AUTOSAR XML (schema 4-2-2)
package /STELLANTIS/EPT/ASWCs
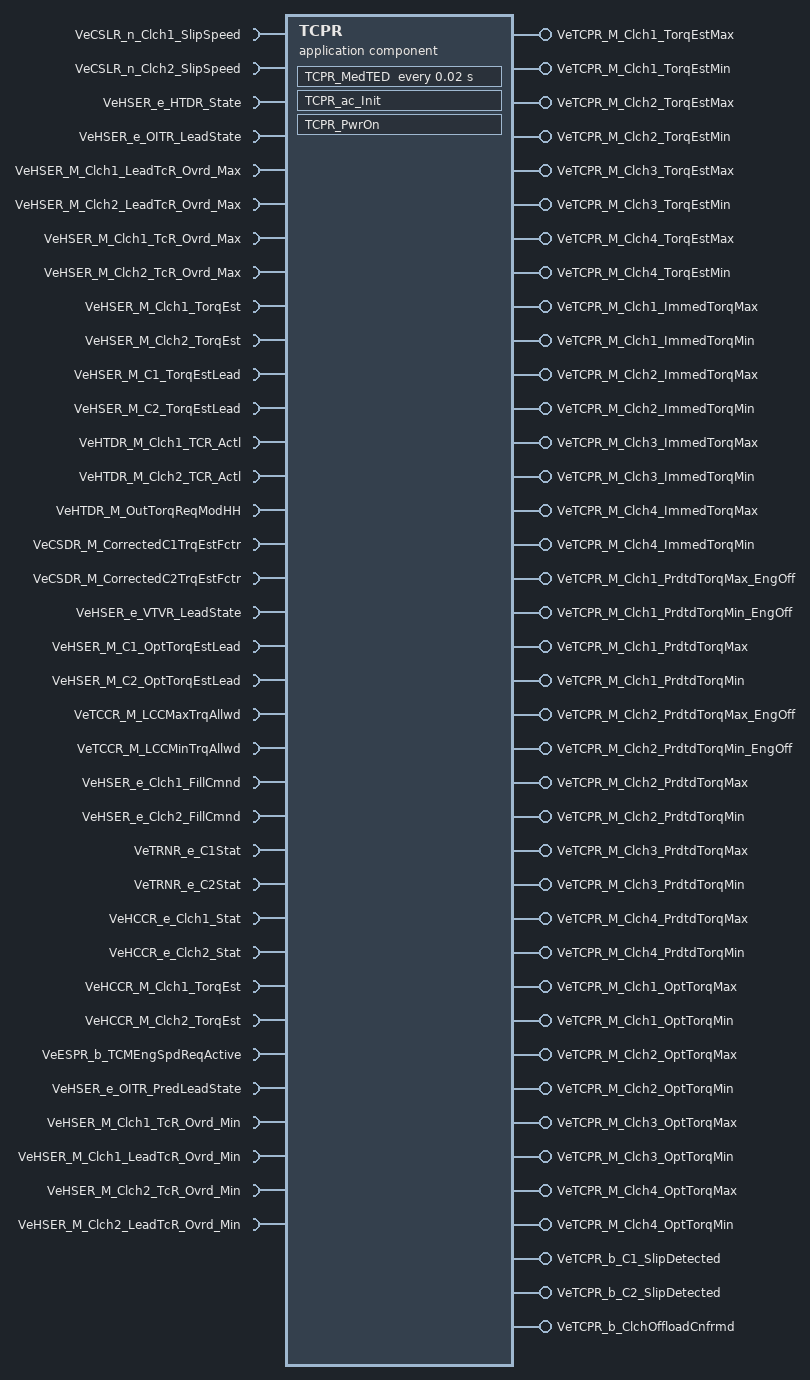
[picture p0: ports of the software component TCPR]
  application sw component type TCPR
    36 x require port:
      VeCSLR_n_Clch1_SlipSpeed: variation-point={short-label=vpVeCSLR_n_Clch1_SlipSpeed, sw-syscond=1}, nonqueued-receiver-com-spec{data-element=Value, init-value=0}, required-interface=VeCSLR_n_Clch1_SlipSpeed
      VeCSLR_n_Clch2_SlipSpeed: variation-point={short-label=vpVeCSLR_n_Clch2_SlipSpeed, sw-syscond=1}, nonqueued-receiver-com-spec{data-element=Value, init-value=0}, required-interface=VeCSLR_n_Clch2_SlipSpeed
      VeHSER_e_HTDR_State: variation-point={short-label=vpVeHSER_e_HTDR_State, sw-syscond=1}, nonqueued-receiver-com-spec{data-element=Value, init-value=CeHSER_e_Neut_State}, required-interface=VeHSER_e_HTDR_State
      VeHSER_e_OITR_LeadState: variation-point={short-label=vpVeHSER_e_OITR_LeadState, sw-syscond=1}, nonqueued-receiver-com-spec{data-element=Value, init-value=CeHSER_e_Neut_State}, required-interface=VeHSER_e_OITR_LeadState
      VeHSER_M_Clch1_LeadTcR_Ovrd_Max: variation-point={short-label=vpVeHSER_M_Clch1_LeadTcR_Ovrd_Max, sw-syscond=1}, nonqueued-receiver-com-spec{data-element=Value, init-value=0}, required-interface=VeHSER_M_Clch1_LeadTcR_Ovrd_Max
      VeHSER_M_Clch2_LeadTcR_Ovrd_Max: variation-point={short-label=vpVeHSER_M_Clch2_LeadTcR_Ovrd_Max, sw-syscond=1}, nonqueued-receiver-com-spec{data-element=Value, init-value=0}, required-interface=VeHSER_M_Clch2_LeadTcR_Ovrd_Max
      VeHSER_M_Clch1_TcR_Ovrd_Max: variation-point={short-label=vpVeHSER_M_Clch1_TcR_Ovrd_Max, sw-syscond=1}, nonqueued-receiver-com-spec{data-element=Value, init-value=0}, required-interface=VeHSER_M_Clch1_TcR_Ovrd_Max
      VeHSER_M_Clch2_TcR_Ovrd_Max: variation-point={short-label=vpVeHSER_M_Clch2_TcR_Ovrd_Max, sw-syscond=1}, nonqueued-receiver-com-spec{data-element=Value, init-value=0}, required-interface=VeHSER_M_Clch2_TcR_Ovrd_Max
      VeHSER_M_Clch1_TorqEst: variation-point={short-label=vpVeHSER_M_Clch1_TorqEst, sw-syscond=1}, nonqueued-receiver-com-spec{data-element=Value, init-value=0}, required-interface=VeHSER_M_Clch1_TorqEst
      VeHSER_M_Clch2_TorqEst: variation-point={short-label=vpVeHSER_M_Clch2_TorqEst, sw-syscond=1}, nonqueued-receiver-com-spec{data-element=Value, init-value=0}, required-interface=VeHSER_M_Clch2_TorqEst
      VeHSER_M_C1_TorqEstLead: variation-point={short-label=vpVeHSER_M_C1_TorqEstLead, sw-syscond=1}, nonqueued-receiver-com-spec{data-element=Value, init-value=0}, required-interface=VeHSER_M_C1_TorqEstLead
      VeHSER_M_C2_TorqEstLead: variation-point={short-label=vpVeHSER_M_C2_TorqEstLead, sw-syscond=1}, nonqueued-receiver-com-spec{data-element=Value, init-value=0}, required-interface=VeHSER_M_C2_TorqEstLead
      VeHTDR_M_Clch1_TCR_Actl: variation-point={short-label=vpVeHTDR_M_Clch1_TCR_Actl, sw-syscond=1}, nonqueued-receiver-com-spec{data-element=Value, init-value=0}, required-interface=VeHTDR_M_Clch1_TCR_Actl
      VeHTDR_M_Clch2_TCR_Actl: variation-point={short-label=vpVeHTDR_M_Clch2_TCR_Actl, sw-syscond=1}, nonqueued-receiver-com-spec{data-element=Value, init-value=0}, required-interface=VeHTDR_M_Clch2_TCR_Actl
      VeHTDR_M_OutTorqReqModHH: variation-point={short-label=vpVeHTDR_M_OutTorqReqModHH, sw-syscond=1}, nonqueued-receiver-com-spec{data-element=Value, init-value=0}, required-interface=VeHTDR_M_OutTorqReqModHH
      VeCSDR_M_CorrectedC1TrqEstFctr: variation-point={short-label=vpVeCSDR_M_CorrectedC1TrqEstFctr, sw-syscond=1}, nonqueued-receiver-com-spec{data-element=Value, init-value=0}, required-interface=VeCSDR_M_CorrectedC1TrqEstFctr
      VeCSDR_M_CorrectedC2TrqEstFctr: variation-point={short-label=vpVeCSDR_M_CorrectedC2TrqEstFctr, sw-syscond=1}, nonqueued-receiver-com-spec{data-element=Value, init-value=0}, required-interface=VeCSDR_M_CorrectedC2TrqEstFctr
      VeHSER_e_VTVR_LeadState: variation-point={short-label=vpVeHSER_e_VTVR_LeadState, sw-syscond=1}, nonqueued-receiver-com-spec{data-element=Value, init-value=CeHSER_e_Neut_State}, required-interface=VeHSER_e_VTVR_LeadState
      VeHSER_M_C1_OptTorqEstLead: variation-point={short-label=vpVeHSER_M_C1_OptTorqEstLead, sw-syscond=1}, nonqueued-receiver-com-spec{data-element=Value, init-value=0}, required-interface=VeHSER_M_C1_OptTorqEstLead
      VeHSER_M_C2_OptTorqEstLead: variation-point={short-label=vpVeHSER_M_C2_OptTorqEstLead, sw-syscond=1}, nonqueued-receiver-com-spec{data-element=Value, init-value=0}, required-interface=VeHSER_M_C2_OptTorqEstLead
      VeTCCR_M_LCCMaxTrqAllwd: variation-point={short-label=vpVeTCCR_M_LCCMaxTrqAllwd, sw-syscond=1}, nonqueued-receiver-com-spec{data-element=Value, init-value=0}, required-interface=VeTCCR_M_LCCMaxTrqAllwd
      VeTCCR_M_LCCMinTrqAllwd: variation-point={short-label=vpVeTCCR_M_LCCMinTrqAllwd, sw-syscond=1}, nonqueued-receiver-com-spec{data-element=Value, init-value=0}, required-interface=VeTCCR_M_LCCMinTrqAllwd
      VeHSER_e_Clch1_FillCmnd: variation-point={short-label=vpVeHSER_e_Clch1_FillCmnd, sw-syscond=1}, nonqueued-receiver-com-spec{data-element=Value, init-value=CeHSER_e_ClchExhstCmpltly}, required-interface=VeHSER_e_Clch1_FillCmnd
      VeHSER_e_Clch2_FillCmnd: variation-point={short-label=vpVeHSER_e_Clch2_FillCmnd, sw-syscond=1}, nonqueued-receiver-com-spec{data-element=Value, init-value=CeHSER_e_ClchExhstCmpltly}, required-interface=VeHSER_e_Clch2_FillCmnd
      VeTRNR_e_C1Stat: variation-point={short-label=vpVeTRNR_e_C1Stat, sw-syscond=1}, nonqueued-receiver-com-spec{data-element=Value, init-value=CeHCCR_e_ClInvalid}, required-interface=VeTRNR_e_C1Stat
      VeTRNR_e_C2Stat: variation-point={short-label=vpVeTRNR_e_C2Stat, sw-syscond=1}, nonqueued-receiver-com-spec{data-element=Value, init-value=CeHCCR_e_ClInvalid}, required-interface=VeTRNR_e_C2Stat
      VeHCCR_e_Clch1_Stat: nonqueued-receiver-com-spec{data-element=Value, init-value=CeHCCR_e_ClInvalid}, required-interface=VeHCCR_e_Clch1_Stat
      VeHCCR_e_Clch2_Stat: nonqueued-receiver-com-spec{data-element=Value, init-value=CeHCCR_e_ClInvalid}, required-interface=VeHCCR_e_Clch2_Stat
      VeHCCR_M_Clch1_TorqEst: variation-point={short-label=vpVeHCCR_M_Clch1_TorqEst, sw-syscond=1}, nonqueued-receiver-com-spec{data-element=Value, init-value=0}, required-interface=VeHCCR_M_Clch1_TorqEst
      VeHCCR_M_Clch2_TorqEst: variation-point={short-label=vpVeHCCR_M_Clch2_TorqEst, sw-syscond=1}, nonqueued-receiver-com-spec{data-element=Value, init-value=0}, required-interface=VeHCCR_M_Clch2_TorqEst
      VeESPR_b_TCMEngSpdReqActive: variation-point={short-label=vpVeESPR_b_TCMEngSpdReqActive, sw-syscond=1}, nonqueued-receiver-com-spec{data-element=Value, init-value=0}, required-interface=VeESPR_b_TCMEngSpdReqActive
      VeHSER_e_OITR_PredLeadState: variation-point={short-label=vpVeHSER_e_OITR_PredLeadState, sw-syscond=1}, nonqueued-receiver-com-spec{data-element=Value, init-value=CeHSER_e_Neut_State}, required-interface=VeHSER_e_OITR_PredLeadState
      VeHSER_M_Clch1_TcR_Ovrd_Min: variation-point={short-label=vpVeHSER_M_Clch1_TcR_Ovrd_Min, sw-syscond=1}, nonqueued-receiver-com-spec{data-element=Value, init-value=0}, required-interface=VeHSER_M_Clch1_TcR_Ovrd_Min
      VeHSER_M_Clch1_LeadTcR_Ovrd_Min: variation-point={short-label=vpVeHSER_M_Clch1_LeadTcR_Ovrd_Min, sw-syscond=1}, nonqueued-receiver-com-spec{data-element=Value, init-value=0}, required-interface=VeHSER_M_Clch1_LeadTcR_Ovrd_Min
      VeHSER_M_Clch2_TcR_Ovrd_Min: variation-point={short-label=vpVeHSER_M_Clch2_TcR_Ovrd_Min, sw-syscond=1}, nonqueued-receiver-com-spec{data-element=Value, init-value=0}, required-interface=VeHSER_M_Clch2_TcR_Ovrd_Min
      VeHSER_M_Clch2_LeadTcR_Ovrd_Min: variation-point={short-label=vpVeHSER_M_Clch2_LeadTcR_Ovrd_Min, sw-syscond=1}, nonqueued-receiver-com-spec{data-element=Value, init-value=0}, required-interface=VeHSER_M_Clch2_LeadTcR_Ovrd_Min
    39 x provide port, all with nonqueued-sender-com-spec{data-element=Value, init-value=0}:
      VeTCPR_M_Clch1_TorqEstMax: provided-interface=VeTCPR_M_Clch1_TorqEstMax
      VeTCPR_M_Clch1_TorqEstMin: provided-interface=VeTCPR_M_Clch1_TorqEstMin
      VeTCPR_M_Clch2_TorqEstMax: provided-interface=VeTCPR_M_Clch2_TorqEstMax
      VeTCPR_M_Clch2_TorqEstMin: provided-interface=VeTCPR_M_Clch2_TorqEstMin
      VeTCPR_M_Clch3_TorqEstMax: provided-interface=VeTCPR_M_Clch3_TorqEstMax
      VeTCPR_M_Clch3_TorqEstMin: provided-interface=VeTCPR_M_Clch3_TorqEstMin
      VeTCPR_M_Clch4_TorqEstMax: provided-interface=VeTCPR_M_Clch4_TorqEstMax
      VeTCPR_M_Clch4_TorqEstMin: provided-interface=VeTCPR_M_Clch4_TorqEstMin
      VeTCPR_M_Clch1_ImmedTorqMax: provided-interface=VeTCPR_M_Clch1_ImmedTorqMax
      VeTCPR_M_Clch1_ImmedTorqMin: provided-interface=VeTCPR_M_Clch1_ImmedTorqMin
      VeTCPR_M_Clch2_ImmedTorqMax: provided-interface=VeTCPR_M_Clch2_ImmedTorqMax
      VeTCPR_M_Clch2_ImmedTorqMin: provided-interface=VeTCPR_M_Clch2_ImmedTorqMin
      VeTCPR_M_Clch3_ImmedTorqMax: provided-interface=VeTCPR_M_Clch3_ImmedTorqMax
      VeTCPR_M_Clch3_ImmedTorqMin: provided-interface=VeTCPR_M_Clch3_ImmedTorqMin
      VeTCPR_M_Clch4_ImmedTorqMax: provided-interface=VeTCPR_M_Clch4_ImmedTorqMax
      VeTCPR_M_Clch4_ImmedTorqMin: provided-interface=VeTCPR_M_Clch4_ImmedTorqMin
      VeTCPR_M_Clch1_PrdtdTorqMax_EngOff: provided-interface=VeTCPR_M_Clch1_PrdtdTorqMax_EngOff
      VeTCPR_M_Clch1_PrdtdTorqMin_EngOff: provided-interface=VeTCPR_M_Clch1_PrdtdTorqMin_EngOff
      VeTCPR_M_Clch1_PrdtdTorqMax: provided-interface=VeTCPR_M_Clch1_PrdtdTorqMax
      VeTCPR_M_Clch1_PrdtdTorqMin: provided-interface=VeTCPR_M_Clch1_PrdtdTorqMin
      VeTCPR_M_Clch2_PrdtdTorqMax_EngOff: provided-interface=VeTCPR_M_Clch2_PrdtdTorqMax_EngOff
      VeTCPR_M_Clch2_PrdtdTorqMin_EngOff: provided-interface=VeTCPR_M_Clch2_PrdtdTorqMin_EngOff
      VeTCPR_M_Clch2_PrdtdTorqMax: provided-interface=VeTCPR_M_Clch2_PrdtdTorqMax
      VeTCPR_M_Clch2_PrdtdTorqMin: provided-interface=VeTCPR_M_Clch2_PrdtdTorqMin
      VeTCPR_M_Clch3_PrdtdTorqMax: provided-interface=VeTCPR_M_Clch3_PrdtdTorqMax
      VeTCPR_M_Clch3_PrdtdTorqMin: provided-interface=VeTCPR_M_Clch3_PrdtdTorqMin
      VeTCPR_M_Clch4_PrdtdTorqMax: provided-interface=VeTCPR_M_Clch4_PrdtdTorqMax
      VeTCPR_M_Clch4_PrdtdTorqMin: provided-interface=VeTCPR_M_Clch4_PrdtdTorqMin
      VeTCPR_M_Clch1_OptTorqMax: provided-interface=VeTCPR_M_Clch1_OptTorqMax
      VeTCPR_M_Clch1_OptTorqMin: provided-interface=VeTCPR_M_Clch1_OptTorqMin
      VeTCPR_M_Clch2_OptTorqMax: provided-interface=VeTCPR_M_Clch2_OptTorqMax
      VeTCPR_M_Clch2_OptTorqMin: provided-interface=VeTCPR_M_Clch2_OptTorqMin
      VeTCPR_M_Clch3_OptTorqMax: provided-interface=VeTCPR_M_Clch3_OptTorqMax
      VeTCPR_M_Clch3_OptTorqMin: provided-interface=VeTCPR_M_Clch3_OptTorqMin
      VeTCPR_M_Clch4_OptTorqMax: provided-interface=VeTCPR_M_Clch4_OptTorqMax
      VeTCPR_M_Clch4_OptTorqMin: provided-interface=VeTCPR_M_Clch4_OptTorqMin
      VeTCPR_b_C1_SlipDetected: provided-interface=VeTCPR_b_C1_SlipDetected
      VeTCPR_b_C2_SlipDetected: provided-interface=VeTCPR_b_C2_SlipDetected
      VeTCPR_b_ClchOffloadCnfrmd: provided-interface=VeTCPR_b_ClchOffloadCnfrmd
    behavior IB_TCPR: data-type-mapping=msADTtoIDTMapping, handle-termination-and-restart=NO-SUPPORT
      timing event Event_MedTED: start-on-event=TCPR_MedTED, period=0.02
      init event Event_TCPR_ac_Init: start-on-event=TCPR_ac_Init
      init event Event_PwrOn: start-on-event=TCPR_PwrOn
      runnable TCPR_ac_Init
      runnable TCPR_PwrOn
        data-send-points:
          39 x access:
            OUT_VeTCPR_M_Clch1_TorqEstMax_Value: accessed-variable=VeTCPR_M_Clch1_TorqEstMax.Value
            OUT_VeTCPR_M_Clch1_TorqEstMin_Value: accessed-variable=VeTCPR_M_Clch1_TorqEstMin.Value
            OUT_VeTCPR_M_Clch2_ImmedTorqMax_Value: accessed-variable=VeTCPR_M_Clch2_ImmedTorqMax.Value
            OUT_VeTCPR_M_Clch2_ImmedTorqMin_Value: accessed-variable=VeTCPR_M_Clch2_ImmedTorqMin.Value
            OUT_VeTCPR_M_Clch3_ImmedTorqMax_Value: accessed-variable=VeTCPR_M_Clch3_ImmedTorqMax.Value
            OUT_VeTCPR_M_Clch3_ImmedTorqMin_Value: accessed-variable=VeTCPR_M_Clch3_ImmedTorqMin.Value
            OUT_VeTCPR_M_Clch4_ImmedTorqMax_Value: accessed-variable=VeTCPR_M_Clch4_ImmedTorqMax.Value
            OUT_VeTCPR_M_Clch4_ImmedTorqMin_Value: accessed-variable=VeTCPR_M_Clch4_ImmedTorqMin.Value
            OUT_VeTCPR_M_Clch1_OptTorqMax_Value: accessed-variable=VeTCPR_M_Clch1_OptTorqMax.Value
            OUT_VeTCPR_M_Clch1_OptTorqMin_Value: accessed-variable=VeTCPR_M_Clch1_OptTorqMin.Value
            OUT_VeTCPR_M_Clch2_OptTorqMax_Value: accessed-variable=VeTCPR_M_Clch2_OptTorqMax.Value
            OUT_VeTCPR_M_Clch2_OptTorqMin_Value: accessed-variable=VeTCPR_M_Clch2_OptTorqMin.Value
            OUT_VeTCPR_M_Clch2_TorqEstMax_Value: accessed-variable=VeTCPR_M_Clch2_TorqEstMax.Value
            OUT_VeTCPR_M_Clch3_OptTorqMax_Value: accessed-variable=VeTCPR_M_Clch3_OptTorqMax.Value
            OUT_VeTCPR_M_Clch3_OptTorqMin_Value: accessed-variable=VeTCPR_M_Clch3_OptTorqMin.Value
            OUT_VeTCPR_M_Clch4_OptTorqMax_Value: accessed-variable=VeTCPR_M_Clch4_OptTorqMax.Value
            OUT_VeTCPR_M_Clch4_OptTorqMin_Value: accessed-variable=VeTCPR_M_Clch4_OptTorqMin.Value
            OUT_VeTCPR_b_C1_SlipDetected_Value: accessed-variable=VeTCPR_b_C1_SlipDetected.Value
            OUT_VeTCPR_b_C2_SlipDetected_Value: accessed-variable=VeTCPR_b_C2_SlipDetected.Value
            OUT_VeTCPR_b_ClchOffloadCnfrmd_Value: accessed-variable=VeTCPR_b_ClchOffloadCnfrmd.Value
            OUT_VeTCPR_M_Clch{1..3}_PrdtdTorqMax_Value: accessed-variable=VeTCPR_M_Clch{1..3}_PrdtdTorqMax.Value
            OUT_VeTCPR_M_Clch2_TorqEstMin_Value: accessed-variable=VeTCPR_M_Clch2_TorqEstMin.Value
            OUT_VeTCPR_M_Clch4_PrdtdTorqMax_Value: accessed-variable=VeTCPR_M_Clch4_PrdtdTorqMax.Value
            OUT_VeTCPR_M_Clch{1..4}_PrdtdTorqMin_Value: accessed-variable=VeTCPR_M_Clch{1..4}_PrdtdTorqMin.Value
            OUT_VeTCPR_M_Clch1_PrdtdTorqMax_EngOff_Value: accessed-variable=VeTCPR_M_Clch1_PrdtdTorqMax_EngOff.Value
            OUT_VeTCPR_M_Clch1_PrdtdTorqMin_EngOff_Value: accessed-variable=VeTCPR_M_Clch1_PrdtdTorqMin_EngOff.Value
            OUT_VeTCPR_M_Clch2_PrdtdTorqMax_EngOff_Value: accessed-variable=VeTCPR_M_Clch2_PrdtdTorqMax_EngOff.Value
            OUT_VeTCPR_M_Clch2_PrdtdTorqMin_EngOff_Value: accessed-variable=VeTCPR_M_Clch2_PrdtdTorqMin_EngOff.Value
            OUT_VeTCPR_M_Clch3_TorqEstMax_Value: accessed-variable=VeTCPR_M_Clch3_TorqEstMax.Value
            OUT_VeTCPR_M_Clch3_TorqEstMin_Value: accessed-variable=VeTCPR_M_Clch3_TorqEstMin.Value
            OUT_VeTCPR_M_Clch4_TorqEstMax_Value: accessed-variable=VeTCPR_M_Clch4_TorqEstMax.Value
            OUT_VeTCPR_M_Clch4_TorqEstMin_Value: accessed-variable=VeTCPR_M_Clch4_TorqEstMin.Value
            OUT_VeTCPR_M_Clch1_ImmedTorqMax_Value: accessed-variable=VeTCPR_M_Clch1_ImmedTorqMax.Value
            OUT_VeTCPR_M_Clch1_ImmedTorqMin_Value: accessed-variable=VeTCPR_M_Clch1_ImmedTorqMin.Value
      runnable TCPR_MedTED
        data-receive-point-by-arguments:
          34 x access:
            IN_VeCSDR_M_CorrectedC1TrqEstFctr_Value: accessed-variable=VeCSDR_M_CorrectedC1TrqEstFctr.Value, variation-point={short-label=vpIN_VeCSDR_M_CorrectedC1TrqEstFctr_Value, sw-syscond=1}
            IN_VeCSDR_M_CorrectedC2TrqEstFctr_Value: accessed-variable=VeCSDR_M_CorrectedC2TrqEstFctr.Value, variation-point={short-label=vpIN_VeCSDR_M_CorrectedC2TrqEstFctr_Value, sw-syscond=1}
            IN_VeCSLR_n_Clch1_SlipSpeed_Value: accessed-variable=VeCSLR_n_Clch1_SlipSpeed.Value, variation-point={short-label=vpIN_VeCSLR_n_Clch1_SlipSpeed_Value, sw-syscond=1}
            IN_VeCSLR_n_Clch2_SlipSpeed_Value: accessed-variable=VeCSLR_n_Clch2_SlipSpeed.Value, variation-point={short-label=vpIN_VeCSLR_n_Clch2_SlipSpeed_Value, sw-syscond=1}
            IN_VeESPR_b_TCMEngSpdReqActive_Value: accessed-variable=VeESPR_b_TCMEngSpdReqActive.Value, variation-point={short-label=vpIN_VeESPR_b_TCMEngSpdReqActive_Value, sw-syscond=1}
            IN_VeHCCR_M_Clch1_TorqEst_Value: accessed-variable=VeHCCR_M_Clch1_TorqEst.Value, variation-point={short-label=vpIN_VeHCCR_M_Clch1_TorqEst_Value, sw-syscond=1}
            IN_VeHCCR_M_Clch2_TorqEst_Value: accessed-variable=VeHCCR_M_Clch2_TorqEst.Value, variation-point={short-label=vpIN_VeHCCR_M_Clch2_TorqEst_Value, sw-syscond=1}
            IN_VeHSER_M_C1_OptTorqEstLead_Value: accessed-variable=VeHSER_M_C1_OptTorqEstLead.Value, variation-point={short-label=vpIN_VeHSER_M_C1_OptTorqEstLead_Value, sw-syscond=1}
            IN_VeHSER_M_C1_TorqEstLead_Value: accessed-variable=VeHSER_M_C1_TorqEstLead.Value, variation-point={short-label=vpIN_VeHSER_M_C1_TorqEstLead_Value, sw-syscond=1}
            IN_VeHSER_M_C2_OptTorqEstLead_Value: accessed-variable=VeHSER_M_C2_OptTorqEstLead.Value, variation-point={short-label=vpIN_VeHSER_M_C2_OptTorqEstLead_Value, sw-syscond=1}
            IN_VeHSER_M_C2_TorqEstLead_Value: accessed-variable=VeHSER_M_C2_TorqEstLead.Value, variation-point={short-label=vpIN_VeHSER_M_C2_TorqEstLead_Value, sw-syscond=1}
            IN_VeHSER_M_Clch1_LeadTcR_Ovrd_Max_Value: accessed-variable=VeHSER_M_Clch1_LeadTcR_Ovrd_Max.Value, variation-point={short-label=vpIN_VeHSER_M_Clch1_LeadTcR_Ovrd_Max_Value, sw-syscond=1}
            IN_VeHSER_M_Clch1_LeadTcR_Ovrd_Min_Value: accessed-variable=VeHSER_M_Clch1_LeadTcR_Ovrd_Min.Value, variation-point={short-label=vpIN_VeHSER_M_Clch1_LeadTcR_Ovrd_Min_Value, sw-syscond=1}
            IN_VeHSER_M_Clch1_TcR_Ovrd_Max_Value: accessed-variable=VeHSER_M_Clch1_TcR_Ovrd_Max.Value, variation-point={short-label=vpIN_VeHSER_M_Clch1_TcR_Ovrd_Max_Value, sw-syscond=1}
            IN_VeHSER_M_Clch1_TcR_Ovrd_Min_Value: accessed-variable=VeHSER_M_Clch1_TcR_Ovrd_Min.Value, variation-point={short-label=vpIN_VeHSER_M_Clch1_TcR_Ovrd_Min_Value, sw-syscond=1}
            IN_VeHSER_M_Clch1_TorqEst_Value: accessed-variable=VeHSER_M_Clch1_TorqEst.Value, variation-point={short-label=vpIN_VeHSER_M_Clch1_TorqEst_Value, sw-syscond=1}
            IN_VeHSER_M_Clch2_LeadTcR_Ovrd_Max_Value: accessed-variable=VeHSER_M_Clch2_LeadTcR_Ovrd_Max.Value, variation-point={short-label=vpIN_VeHSER_M_Clch2_LeadTcR_Ovrd_Max_Value, sw-syscond=1}
            IN_VeHSER_M_Clch2_LeadTcR_Ovrd_Min_Value: accessed-variable=VeHSER_M_Clch2_LeadTcR_Ovrd_Min.Value, variation-point={short-label=vpIN_VeHSER_M_Clch2_LeadTcR_Ovrd_Min_Value, sw-syscond=1}
            IN_VeHSER_M_Clch2_TcR_Ovrd_Max_Value: accessed-variable=VeHSER_M_Clch2_TcR_Ovrd_Max.Value, variation-point={short-label=vpIN_VeHSER_M_Clch2_TcR_Ovrd_Max_Value, sw-syscond=1}
            IN_VeHSER_M_Clch2_TcR_Ovrd_Min_Value: accessed-variable=VeHSER_M_Clch2_TcR_Ovrd_Min.Value, variation-point={short-label=vpIN_VeHSER_M_Clch2_TcR_Ovrd_Min_Value, sw-syscond=1}
            IN_VeHSER_M_Clch2_TorqEst_Value: accessed-variable=VeHSER_M_Clch2_TorqEst.Value, variation-point={short-label=vpIN_VeHSER_M_Clch2_TorqEst_Value, sw-syscond=1}
            IN_VeHSER_e_Clch1_FillCmnd_Value: accessed-variable=VeHSER_e_Clch1_FillCmnd.Value, variation-point={short-label=vpIN_VeHSER_e_Clch1_FillCmnd_Value, sw-syscond=1}
            IN_VeHSER_e_Clch2_FillCmnd_Value: accessed-variable=VeHSER_e_Clch2_FillCmnd.Value, variation-point={short-label=vpIN_VeHSER_e_Clch2_FillCmnd_Value, sw-syscond=1}
            IN_VeHSER_e_HTDR_State_Value: accessed-variable=VeHSER_e_HTDR_State.Value, variation-point={short-label=vpIN_VeHSER_e_HTDR_State_Value, sw-syscond=1}
            IN_VeHSER_e_OITR_LeadState_Value: accessed-variable=VeHSER_e_OITR_LeadState.Value, variation-point={short-label=vpIN_VeHSER_e_OITR_LeadState_Value, sw-syscond=1}
            IN_VeHSER_e_OITR_PredLeadState_Value: accessed-variable=VeHSER_e_OITR_PredLeadState.Value, variation-point={short-label=vpIN_VeHSER_e_OITR_PredLeadState_Value, sw-syscond=1}
            IN_VeHSER_e_VTVR_LeadState_Value: accessed-variable=VeHSER_e_VTVR_LeadState.Value, variation-point={short-label=vpIN_VeHSER_e_VTVR_LeadState_Value, sw-syscond=1}
            IN_VeHTDR_M_Clch1_TCR_Actl_Value: accessed-variable=VeHTDR_M_Clch1_TCR_Actl.Value, variation-point={short-label=vpIN_VeHTDR_M_Clch1_TCR_Actl_Value, sw-syscond=1}
            IN_VeHTDR_M_Clch2_TCR_Actl_Value: accessed-variable=VeHTDR_M_Clch2_TCR_Actl.Value, variation-point={short-label=vpIN_VeHTDR_M_Clch2_TCR_Actl_Value, sw-syscond=1}
            IN_VeHTDR_M_OutTorqReqModHH_Value: accessed-variable=VeHTDR_M_OutTorqReqModHH.Value, variation-point={short-label=vpIN_VeHTDR_M_OutTorqReqModHH_Value, sw-syscond=1}
            IN_VeTCCR_M_LCCMaxTrqAllwd_Value: accessed-variable=VeTCCR_M_LCCMaxTrqAllwd.Value, variation-point={short-label=vpIN_VeTCCR_M_LCCMaxTrqAllwd_Value, sw-syscond=1}
            IN_VeTCCR_M_LCCMinTrqAllwd_Value: accessed-variable=VeTCCR_M_LCCMinTrqAllwd.Value, variation-point={short-label=vpIN_VeTCCR_M_LCCMinTrqAllwd_Value, sw-syscond=1}
            IN_VeTRNR_e_C1Stat_Value: accessed-variable=VeTRNR_e_C1Stat.Value, variation-point={short-label=vpIN_VeTRNR_e_C1Stat_Value, sw-syscond=1}
            IN_VeTRNR_e_C2Stat_Value: accessed-variable=VeTRNR_e_C2Stat.Value, variation-point={short-label=vpIN_VeTRNR_e_C2Stat_Value, sw-syscond=1}
        data-send-points:
          39 x access:
            OUT_VeTCPR_M_Clch1_TorqEstMax_Value: accessed-variable=VeTCPR_M_Clch1_TorqEstMax.Value
            OUT_VeTCPR_M_Clch1_TorqEstMin_Value: accessed-variable=VeTCPR_M_Clch1_TorqEstMin.Value
            OUT_VeTCPR_M_Clch2_ImmedTorqMax_Value: accessed-variable=VeTCPR_M_Clch2_ImmedTorqMax.Value
            OUT_VeTCPR_M_Clch2_ImmedTorqMin_Value: accessed-variable=VeTCPR_M_Clch2_ImmedTorqMin.Value
            OUT_VeTCPR_M_Clch3_ImmedTorqMax_Value: accessed-variable=VeTCPR_M_Clch3_ImmedTorqMax.Value
            OUT_VeTCPR_M_Clch3_ImmedTorqMin_Value: accessed-variable=VeTCPR_M_Clch3_ImmedTorqMin.Value
            OUT_VeTCPR_M_Clch4_ImmedTorqMax_Value: accessed-variable=VeTCPR_M_Clch4_ImmedTorqMax.Value
            OUT_VeTCPR_M_Clch4_ImmedTorqMin_Value: accessed-variable=VeTCPR_M_Clch4_ImmedTorqMin.Value
            OUT_VeTCPR_M_Clch1_OptTorqMax_Value: accessed-variable=VeTCPR_M_Clch1_OptTorqMax.Value
            OUT_VeTCPR_M_Clch1_OptTorqMin_Value: accessed-variable=VeTCPR_M_Clch1_OptTorqMin.Value
            OUT_VeTCPR_M_Clch2_OptTorqMax_Value: accessed-variable=VeTCPR_M_Clch2_OptTorqMax.Value
            OUT_VeTCPR_M_Clch2_OptTorqMin_Value: accessed-variable=VeTCPR_M_Clch2_OptTorqMin.Value
            OUT_VeTCPR_M_Clch2_TorqEstMax_Value: accessed-variable=VeTCPR_M_Clch2_TorqEstMax.Value
            OUT_VeTCPR_M_Clch3_OptTorqMax_Value: accessed-variable=VeTCPR_M_Clch3_OptTorqMax.Value
            OUT_VeTCPR_M_Clch3_OptTorqMin_Value: accessed-variable=VeTCPR_M_Clch3_OptTorqMin.Value
            OUT_VeTCPR_M_Clch4_OptTorqMax_Value: accessed-variable=VeTCPR_M_Clch4_OptTorqMax.Value
            OUT_VeTCPR_M_Clch4_OptTorqMin_Value: accessed-variable=VeTCPR_M_Clch4_OptTorqMin.Value
            OUT_VeTCPR_b_C1_SlipDetected_Value: accessed-variable=VeTCPR_b_C1_SlipDetected.Value
            OUT_VeTCPR_b_C2_SlipDetected_Value: accessed-variable=VeTCPR_b_C2_SlipDetected.Value
            OUT_VeTCPR_b_ClchOffloadCnfrmd_Value: accessed-variable=VeTCPR_b_ClchOffloadCnfrmd.Value
            OUT_VeTCPR_M_Clch{1..3}_PrdtdTorqMax_Value: accessed-variable=VeTCPR_M_Clch{1..3}_PrdtdTorqMax.Value
            OUT_VeTCPR_M_Clch2_TorqEstMin_Value: accessed-variable=VeTCPR_M_Clch2_TorqEstMin.Value
            OUT_VeTCPR_M_Clch4_PrdtdTorqMax_Value: accessed-variable=VeTCPR_M_Clch4_PrdtdTorqMax.Value
            OUT_VeTCPR_M_Clch{1..4}_PrdtdTorqMin_Value: accessed-variable=VeTCPR_M_Clch{1..4}_PrdtdTorqMin.Value
            OUT_VeTCPR_M_Clch1_PrdtdTorqMax_EngOff_Value: accessed-variable=VeTCPR_M_Clch1_PrdtdTorqMax_EngOff.Value
            OUT_VeTCPR_M_Clch1_PrdtdTorqMin_EngOff_Value: accessed-variable=VeTCPR_M_Clch1_PrdtdTorqMin_EngOff.Value
            OUT_VeTCPR_M_Clch2_PrdtdTorqMax_EngOff_Value: accessed-variable=VeTCPR_M_Clch2_PrdtdTorqMax_EngOff.Value
            OUT_VeTCPR_M_Clch2_PrdtdTorqMin_EngOff_Value: accessed-variable=VeTCPR_M_Clch2_PrdtdTorqMin_EngOff.Value
            OUT_VeTCPR_M_Clch3_TorqEstMax_Value: accessed-variable=VeTCPR_M_Clch3_TorqEstMax.Value
            OUT_VeTCPR_M_Clch3_TorqEstMin_Value: accessed-variable=VeTCPR_M_Clch3_TorqEstMin.Value
            OUT_VeTCPR_M_Clch4_TorqEstMax_Value: accessed-variable=VeTCPR_M_Clch4_TorqEstMax.Value
            OUT_VeTCPR_M_Clch4_TorqEstMin_Value: accessed-variable=VeTCPR_M_Clch4_TorqEstMin.Value
            OUT_VeTCPR_M_Clch1_ImmedTorqMax_Value: accessed-variable=VeTCPR_M_Clch1_ImmedTorqMax.Value
            OUT_VeTCPR_M_Clch1_ImmedTorqMin_Value: accessed-variable=VeTCPR_M_Clch1_ImmedTorqMin.Value
      5 x variation point proxy, all with category=CONDITION:
        Variant_TCPR_1: condition-access=0
        Variant_TCPR_3: condition-access=1
        Variant_TCPR_5: condition-access=0
        Variant_TCPR_7: condition-access=1
        Variant_TCPR_9: condition-access=1
